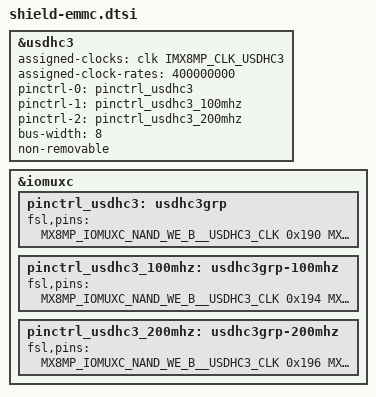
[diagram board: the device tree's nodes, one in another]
// SPDX-License-Identifier: (GPL-2.0+ OR MIT)
/*
 * Copyright 2025 CriticalShift
 */

#include <dt-bindings/clock/imx8mp-clock.h>


&usdhc3 {
	assigned-clocks = <&clk IMX8MP_CLK_USDHC3>;
	assigned-clock-rates = <400000000>;
	pinctrl-names = "default", "state_100mhz", "state_200mhz";
	pinctrl-0 = <&pinctrl_usdhc3>;
	pinctrl-1 = <&pinctrl_usdhc3_100mhz>;
	pinctrl-2 = <&pinctrl_usdhc3_200mhz>;
	bus-width = <8>;
	non-removable;
	status = "okay";
};

&iomuxc {
	pinctrl_usdhc3: usdhc3grp {
		fsl,pins = <
			MX8MP_IOMUXC_NAND_WE_B__USDHC3_CLK					0x190
			MX8MP_IOMUXC_NAND_WP_B__USDHC3_CMD					0x1d0
			MX8MP_IOMUXC_NAND_DATA04__USDHC3_DATA0				0x1d0
			MX8MP_IOMUXC_NAND_DATA05__USDHC3_DATA1				0x1d0
			MX8MP_IOMUXC_NAND_DATA06__USDHC3_DATA2				0x1d0
			MX8MP_IOMUXC_NAND_DATA07__USDHC3_DATA3				0x1d0
			MX8MP_IOMUXC_NAND_RE_B__USDHC3_DATA4				0x1d0
			MX8MP_IOMUXC_NAND_CE2_B__USDHC3_DATA5				0x1d0
			MX8MP_IOMUXC_NAND_CE3_B__USDHC3_DATA6				0x1d0
			MX8MP_IOMUXC_NAND_CLE__USDHC3_DATA7					0x1d0
			MX8MP_IOMUXC_NAND_CE1_B__USDHC3_STROBE				0x190
		>;
	};

	pinctrl_usdhc3_100mhz: usdhc3grp-100mhz {
		fsl,pins = <
			MX8MP_IOMUXC_NAND_WE_B__USDHC3_CLK					0x194
			MX8MP_IOMUXC_NAND_WP_B__USDHC3_CMD					0x1d4
			MX8MP_IOMUXC_NAND_DATA04__USDHC3_DATA0				0x1d4
			MX8MP_IOMUXC_NAND_DATA05__USDHC3_DATA1				0x1d4
			MX8MP_IOMUXC_NAND_DATA06__USDHC3_DATA2				0x1d4
			MX8MP_IOMUXC_NAND_DATA07__USDHC3_DATA3				0x1d4
			MX8MP_IOMUXC_NAND_RE_B__USDHC3_DATA4				0x1d4
			MX8MP_IOMUXC_NAND_CE2_B__USDHC3_DATA5				0x1d4
			MX8MP_IOMUXC_NAND_CE3_B__USDHC3_DATA6				0x1d4
			MX8MP_IOMUXC_NAND_CLE__USDHC3_DATA7					0x1d4
			MX8MP_IOMUXC_NAND_CE1_B__USDHC3_STROBE				0x194
		>;
	};

	pinctrl_usdhc3_200mhz: usdhc3grp-200mhz {
		fsl,pins = <
			MX8MP_IOMUXC_NAND_WE_B__USDHC3_CLK					0x196
			MX8MP_IOMUXC_NAND_WP_B__USDHC3_CMD					0x1d6
			MX8MP_IOMUXC_NAND_DATA04__USDHC3_DATA0				0x1d6
			MX8MP_IOMUXC_NAND_DATA05__USDHC3_DATA1				0x1d6
			MX8MP_IOMUXC_NAND_DATA06__USDHC3_DATA2				0x1d6
			MX8MP_IOMUXC_NAND_DATA07__USDHC3_DATA3				0x1d6
			MX8MP_IOMUXC_NAND_RE_B__USDHC3_DATA4				0x1d6
			MX8MP_IOMUXC_NAND_CE2_B__USDHC3_DATA5				0x1d6
			MX8MP_IOMUXC_NAND_CE3_B__USDHC3_DATA6				0x1d6
			MX8MP_IOMUXC_NAND_CLE__USDHC3_DATA7					0x1d6
			MX8MP_IOMUXC_NAND_CE1_B__USDHC3_STROBE				0x196
		>;
	};
};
